# R7FA6M1AD register map
Vendor: Renesas; Series: RA6; File version: 1.2
CPU: CM4 r0p1, little endian, MPU, FPU, VTOR, 4 interrupt priority bits
Registers are 8-bit, read-write, reset 0x0 unless marked. A register's access mark holds for its fields unless they carry their own. Offsets are from the block's base; [hi:lo] are bit positions; {n}, {i} and the like mark numbered series.

## SCI0 — Serial Communication Interface 0
Base 0x40070000
Same registers: SCI1 0x40070020, SCI2 0x40070040, SCI3 0x40070060, SCI4 0x40070080, SCI8 0x40070100, SCI9 0x40070120
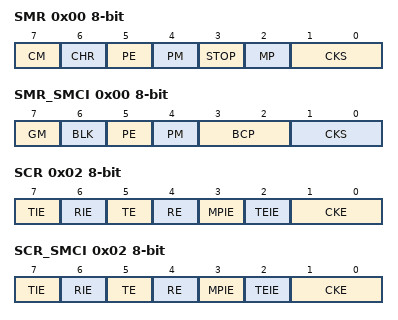
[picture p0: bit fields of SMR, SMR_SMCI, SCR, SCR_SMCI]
0x00 SMR — Serial Mode Register (SCMR.SMIF = 0)
  [7] CM — Communications Mode
  [6] CHR — Character Length (Valid only in asynchronous mode)
  [5] PE — Parity Enable (Valid only in asynchronous mode)
  [4] PM — Parity Mode (Valid only when the PE bit is 1)
  [3] STOP — Stop Bit Length (Valid only in asynchronous mode)
  [2] MP — Multi,Processor Mode (Valid only in asynchronous mode)
  [1:0] CKS — Clock Select
0x00 SMR_SMCI (alternate view of SMR) — Serial mode register (SCMR.SMIF = 1)
  [7] GM — GSM Mode
  [6] BLK — Block Transfer Mode
  [5] PE — Parity Enable (Valid only in asynchronous mode)
  [4] PM — Parity Mode (Valid only when the PE bit is 1)
  [3:2] BCP — Stop Bit Length (Valid only in asynchronous mode)
  [1:0] CKS — Clock Select
0x01 BRR reset 0xFF — Bit Rate Register
  [7:0] BRR — BRR is an 8-bit register that adjusts the bit rate.
0x02 SCR — Serial Control Register (SCMR.SMIF = 0)
  [7] TIE — Transmit Interrupt Enable
  [6] RIE — Receive Interrupt Enable
  [5] TE — Transmit Enable
  [4] RE — Receive Enable
  [3] MPIE — Multi,Processor Interrupt Enable (Valid in asynchronous mode when SMR.MP = 1)
  [2] TEIE — Transmit End Interrupt Enable
  [1:0] CKE — Clock Enable
0x02 SCR_SMCI (alternate view of SCR) — Serial Control Register (SCMR.SMIF =1)
  [7] TIE — Transmit Interrupt Enable
  [6] RIE — Receive Interrupt Enable
  [5] TE — Transmit Enable
  [4] RE — Receive Enable
  [3] MPIE — Multi,Processor Interrupt Enable Set this bit to 0 in smart card interface mode.
  [2] TEIE — Transmit End Interrupt Enable Set this bit to 0 in smart card interface mode.
  [1:0] CKE — Clock Enable
0x03 TDR reset 0xFF — Transmit Data Register
  [7:0] TDR — TDR is an 8-bit register that stores transmit data.
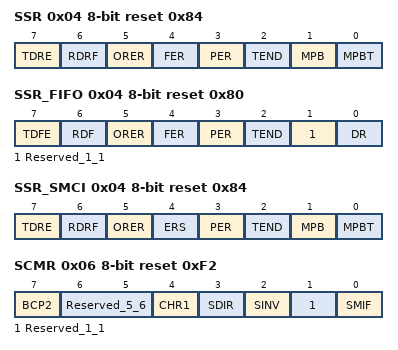
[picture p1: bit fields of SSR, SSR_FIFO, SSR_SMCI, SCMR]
0x04 SSR reset 0x84 — Serial Status Register(SCMR.SMIF = 0 and FCR.FM=0)
  [7] TDRE write-0-clears read-modifies — Transmit Data Empty Flag
  [6] RDRF write-0-clears read-modifies — Receive Data Full Flag
  [5] ORER write-0-clears read-modifies — Overrun Error Flag
  [4] FER write-0-clears read-modifies — Framing Error Flag
  [3] PER write-0-clears read-modifies — Parity Error Flag
  [2] TEND ro — Transmit End Flag
  [1] MPB ro — Multi,Processor Bit. Value of the multi,processor bit in the reception frame
  [0] MPBT — Multi,Processor Bit Transfer. Sets the multi,processor bit for adding to the transmission frame
0x04 SSR_FIFO reset 0x80 (reset mask 0xFD) (alternate view of SSR) — Serial Status Register(SCMR.SMIF = 0 and FCR.FM=1)
  [7] TDFE write-0-clears read-modifies — Transmit FIFO data empty flag
  [6] RDF write-0-clears read-modifies — Receive FIFO data full flag
  [5] ORER write-0-clears read-modifies — Overrun Error Flag
  [4] FER write-0-clears read-modifies — Framing Error Flag
  [3] PER write-0-clears read-modifies — Parity Error Flag
  [2] TEND write-0-clears read-modifies — Transmit End Flag
  [1] Reserved_1_1 — This bit is read as 0. The write value should be 0.
  [0] DR write-0-clears read-modifies — Receive Data Ready flag (Valid only in asynchronous mode(including multi,processor) and FIFO selected)
0x04 SSR_SMCI reset 0x84 (alternate view of SSR) — Serial Status Register(SCMR.SMIF = 1)
  [7] TDRE write-0-clears read-modifies — Transmit Data Empty Flag
  [6] RDRF write-0-clears read-modifies — Receive Data Full Flag
  [5] ORER write-0-clears read-modifies — Overrun Error Flag
  [4] ERS write-0-clears read-modifies — Error Signal Status Flag
  [3] PER write-0-clears read-modifies — Parity Error Flag
  [2] TEND ro — Transmit End Flag
  [1] MPB ro — This bit should be 0 in smart card interface mode.
  [0] MPBT — This bit should be 0 in smart card interface mode.
0x05 RDR ro — Receive Data Register
  [7:0] RDR — RDR is an 8-bit register that stores receive data.
0x06 SCMR reset 0xF2 — Smart Card Mode Register
  [7] BCP2 — Base Clock Pulse 2 Selects the number of base clock cycles in combination with the SMR.BCP[1:0] bits
  [6:5] Reserved_5_6 — These bits are read as 11. The write value should be 11.
  [4] CHR1 — Character Length 1 (Only valid in asynchronous mode)
  [3] SDIR — Transmitted/Received Data Transfer Direction NOTE: The setting is invalid and a fixed data length of 8 bits is used in modes other than asynchronous mode. Set this bit to 1 if operation is to be in simple I2C mode.
  [2] SINV — Transmitted/Received Data Invert Set this bit to 0 if operation is to be in simple I2C mode.
  [1] Reserved_1_1 — This bit is read as 1. The write value should be 1.
  [0] SMIF — Smart Card Interface Mode Select
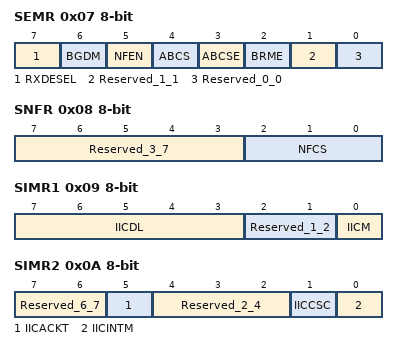
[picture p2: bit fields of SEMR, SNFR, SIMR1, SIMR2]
0x07 SEMR — Serial Extended Mode Register
  [7] RXDESEL — Asynchronous Start Bit Edge Detection Select (Valid only in asynchronous mode)
  [6] BGDM — Baud Rate Generator Double,Speed Mode Select (Only valid the CKE[1] bit in SCR is 0 in asynchronous mode).
  [5] NFEN — Digital Noise Filter Function Enable (The NFEN bit should be 0 without simple I2C mode and asynchronous mode.) In asynchronous mode, for RXDn input only. In simple I2C mode, for RXDn/TxDn input.
  [4] ABCS — Asynchronous Mode Base Clock Select (Valid only in asynchronous mode)
  [3] ABCSE — Asynchronous Mode Extended Base Clock Select1 (Valid only in asynchronous mode and SCR.CKE[1]=0)
  [2] BRME — Bit Modulation Enable
  [1] Reserved_1_1 — This bit is read as 0. The write value should be 0.
  [0] Reserved_0_0 — This bit is read as 0. The write value should be 0.
0x08 SNFR — Noise Filter Setting Register
  [7:3] Reserved_3_7 — These bits are read as 00000. The write value should be 00000.
  [2:0] NFCS — Noise Filter Clock Select
0x09 SIMR1 — I2C Mode Register 1
  [7:3] IICDL — SSDA Delay Output Select Cycles below are of the clock signal from the on,chip baud rate generator.
  [2:1] Reserved_1_2 — These bits are read as 00. The write value should be 00.
  [0] IICM — Simple I2C Mode Select
0x0A SIMR2 — I2C Mode Register 2
  [7:6] Reserved_6_7 — These bits are read as 00. The write value should be 00.
  [5] IICACKT — ACK Transmission Data
  [4:2] Reserved_2_4 — These bits are read as 000. The write value should be 000.
  [1] IICCSC — Clock Synchronization
  [0] IICINTM — I2C Interrupt Mode Select
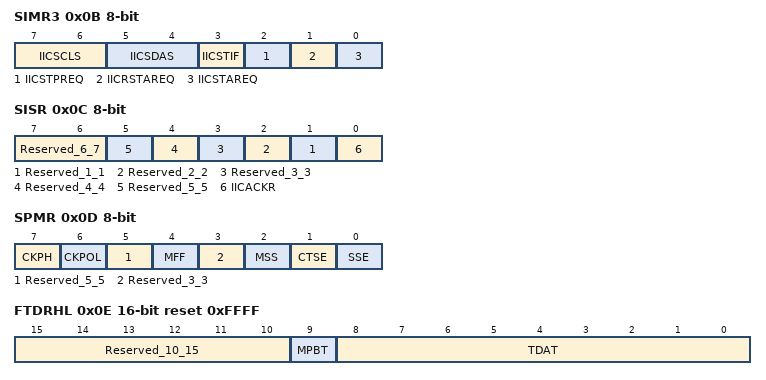
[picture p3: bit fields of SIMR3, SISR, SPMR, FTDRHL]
0x0B SIMR3 — I2C Mode Register 3
  [7:6] IICSCLS — SCL Output Select
  [5:4] IICSDAS — SDA Output Select
  [3] IICSTIF write-0-clears read-modifies — Issuing of Start, Restart, or Stop Condition Completed Flag (When 0 is written to IICSTIF, it is cleared to 0.)
  [2] IICSTPREQ — Stop Condition Generation
  [1] IICRSTAREQ — Restart Condition Generation
  [0] IICSTAREQ — Start Condition Generation
0x0C SISR ro (reset mask 0xCB) — I2C Status Register
  [7:6] Reserved_6_7 — These bits are read as 00.
  [n] Reserved_{n}_{n} (n=1..5) — This bit is read as 0.
  [0] IICACKR — ACK Reception Data Flag
0x0D SPMR — SPI Mode Register
  [7] CKPH — Clock Phase Select
  [6] CKPOL — Clock Polarity Select
  [5] Reserved_5_5 — This bit is read as 0. The write value should be 0.
  [4] MFF write-0-clears read-modifies — Mode Fault Flag
  [3] Reserved_3_3 — This bit is read as 0. The write value should be 0.
  [2] MSS — Master or slave mode selection
  [1] CTSE — CTS Enable
  [0] SSE — SSn# Pin Function Enable
0x0E TDRHL 16-bit reset 0xFFFF — Transmit 9-bit Data Register
  [15:0] TDRHL — TDRHL is a 16-bit register that stores transmit data.
0x0E FTDRHL 16-bit wo reset 0xFFFF (alternate view of TDRHL) — Transmit FIFO Data Register HL
  [15:10] Reserved_10_15 — The write value should be 111111.
  [9] MPBT — Multi,processor transfer bit flag (Valid only in asynchronous mode and SMR.MP=1 and FIFO selected)
  [8:0] TDAT — Serial transmit data (Valid only in asynchronous mode(including multi,processor) or clock synchronous mode, and FIFO selected)
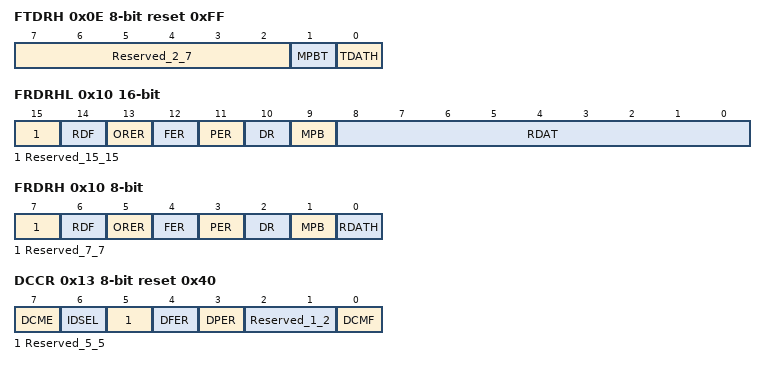
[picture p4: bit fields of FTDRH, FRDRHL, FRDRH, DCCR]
0x0E FTDRH wo reset 0xFF (alternate view of TDRHL) — Transmit FIFO Data Register H
  [7:2] Reserved_2_7 — The write value should be 111111.
  [1] MPBT — Multi,processor transfer bit flag (Valid only in asynchronous mode and SMR.MP=1 and FIFO selected)
  [0] TDATH — Serial transmit data (b8) (Valid only in asynchronous mode(including multi,processor) or clock synchronous mode, and FIFO selected)
0x0F FTDRL wo reset 0xFF (alternate view of TDRHL) — Transmit FIFO Data Register L
  [7:0] TDATL — Serial transmit data(b7-b0) (Valid only in asynchronous mode(including multi,processor) or clock synchronous mode, and FIFO selected)
0x10 RDRHL 16-bit ro — Receive 9-bit Data Register
  [15:0] RDRHL — RDRHL is an 16-bit register that stores receive data.
0x10 FRDRHL 16-bit ro (alternate view of RDRHL) — Receive FIFO Data Register HL
  [15] Reserved_15_15 — This bit is read as 0.
  [14] RDF — Receive FIFO data full flag (It is same as SSR.RDF)
  [13] ORER — Overrun error flag (It is same as SSR.ORER)
  [12] FER — Framing error flag
  [11] PER — Parity error flag
  [10] DR — Receive data ready flag (It is same as SSR.DR)
  [9] MPB — Multi,processor bit flag (Valid only in asynchronous mode with SMR.MP=1 and FIFO selected) It can read multi,processor bit corresponded to serial receive data(RDATA[8:0])
  [8:0] RDAT — Serial receive data (Valid only in asynchronous mode(including multi,processor) or clock synchronous mode, and FIFO selected)
0x10 FRDRH ro (alternate view of RDRHL) — Receive FIFO Data Register H
  [7] Reserved_7_7 — This bit is read as 0.
  [6] RDF — Receive FIFO data full flag (It is same as SSR.RDF)
  [5] ORER — Overrun error flag (It is same as SSR.ORER)
  [4] FER — Framing error flag
  [3] PER — Parity error flag
  [2] DR — Receive data ready flag (It is same as SSR.DR)
  [1] MPB — Multi,processor bit flag (Valid only in asynchronous mode with SMR.MP=1 and FIFO selected) It can read multi,processor bit corresponded to serial receive data(RDATA[8:0])
  [0] RDATH — Serial receive data(b8) (Valid only in asynchronous mode(including multi,processor) or clock synchronous mode, and FIFO selected)
0x11 FRDRL ro (alternate view of RDRHL) — Receive FIFO Data Register L
  [7:0] RDATL — Serial receive data (Valid only in asynchronous mode(including multi,processor) or clock synchronous mode, and FIFO selected) NOTE: When reading both of FRDRH register and FRDRL register, please read by an order of the FRDRH register and the FRDRL register.
0x12 MDDR reset 0xFF — Modulation Duty Register
  [7:0] MDDR — MDDR corrects the bit rate adjusted by the BRR register.
0x13 DCCR reset 0x40 — Data Compare Match Control Register
  [7] DCME — Data Compare Match Enable (Valid only in asynchronous mode(including multi,processor)
  [6] IDSEL — ID frame select Bit (Valid only in asynchronous mode(including multi,processor)
  [5] Reserved_5_5 — This bit is read as 0. The write value should be 0.
  [4] DFER write-0-clears read-modifies — Data Compare Match Framing Error Flag
  [3] DPER write-0-clears read-modifies — Data Compare Match Parity Error Flag
  [2:1] Reserved_1_2 — These bits are read as 00. The write value should be 00.
  [0] DCMF write-0-clears read-modifies — Data Compare Match Flag
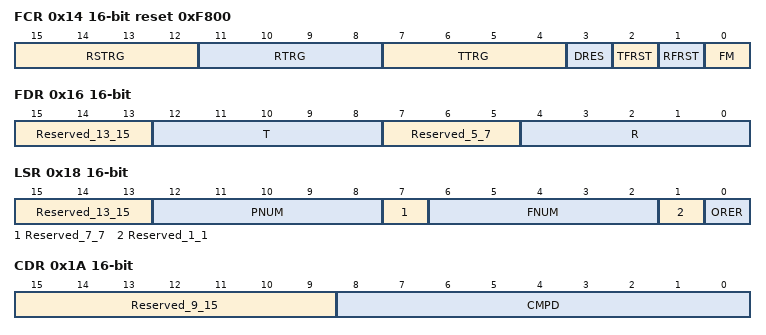
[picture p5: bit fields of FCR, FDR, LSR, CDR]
0x14 FCR 16-bit reset 0xF800 — FIFO Control Register
  [15:12] RSTRG — RTS# Output Active Trigger Number Select (Valid only in asynchronous mode(including multi,processor) or clock synchronous mode)
  [11:8] RTRG — Receive FIFO data trigger number
  [7:4] TTRG — Transmit FIFO data trigger number (Valid only in asynchronous mode(including multi,processor) or clock synchronous mode)
  [3] DRES — Receive data ready error select bit (When detecting a reception data ready, the interrupt request is selected.)
  [2] TFRST — Transmit FIFO Data Register Reset (Valid only in FCR.FM=1)
  [1] RFRST — Receive FIFO Data Register Reset (Valid only in FCR.FM=1)
  [0] FM — FIFO Mode Select (Valid only in asynchronous mode(including multi,processor) or clock synchronous mode)
0x16 FDR 16-bit ro — FIFO Data Count Register
  [15:13] Reserved_13_15 — These bits are read as 000.
  [12:8] T — Transmit FIFO Data Count Indicate the quantity of non,transmit data stored in FTDRH and FTDRL (Valid only in asynchronous mode(including multi,processor) or clock synchronous mode, while FCR.FM=1)
  [7:5] Reserved_5_7 — These bits are read as 000.
  [4:0] R — Receive FIFO Data Count Indicate the quantity of receive data stored in FRDRH and FRDRL (Valid only in asynchronous mode(including multi,processor) or clock synchronous mode, while FCR.FM=1)
0x18 LSR 16-bit ro — Line Status Register
  [15:13] Reserved_13_15 — These bits are read as 000.
  [12:8] PNUM — Parity Error Count Indicates the quantity of data with a parity error among the receive data stored in the receive FIFO data register (FRDRH and FRDRL).
  [7] Reserved_7_7 — This bit is read as 0.
  [6:2] FNUM — Framing Error Count Indicates the quantity of data with a framing error among the receive data stored in the receive FIFO data register (FRDRH and FRDRL).
  [1] Reserved_1_1 — This bit is read as 0.
  [0] ORER — Overrun Error Flag (Valid only in asynchronous mode(including multi,processor) or clock synchronous mode, and FIFO selected)
0x1A CDR 16-bit — Compare Match Data Register
  [15:9] Reserved_9_15 — These bits are read as 0000000. The write value should be 0000000.
  [8:0] CMPD — Compare Match Data Compare data pattern for address match wake,up function
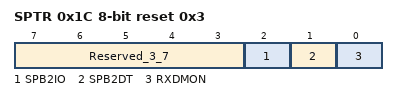
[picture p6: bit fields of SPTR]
0x1C SPTR reset 0x3 — Serial Port Register
  [7:3] Reserved_3_7 — These bits are read as 00000. The write value should be 00000.
  [2] SPB2IO — Serial port break I/O bit (It's selected whether the value of SPB2DT is output to TxD terminal.)
  [1] SPB2DT — Serial port break data select bit (The output level of TxD terminal is selected when SCR.TE = 0.)
  [0] RXDMON ro — Serial input data monitor bit (The state of the RXD terminal is shown.)
